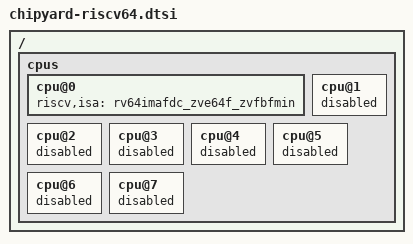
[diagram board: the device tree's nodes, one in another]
/*
 * Copyright (c) 2024 Antmicro <www.antmicro.com>
 *
 * SPDX-License-Identifier: Apache-2.0
 */

/dts-v1/;

#include <chipyard/chipyard-riscv.dtsi>

/ {
	cpus {
		cpu@0 {
			riscv,isa = "rv64imafdc_zve64f_zvfbfmin";
		};

		cpu@1 {
			status = "disabled";
		};

		cpu@2 {
			status = "disabled";
		};

		cpu@3 {
			status = "disabled";
		};

		cpu@4 {
			status = "disabled";
		};

		cpu@5 {
			status = "disabled";
		};

		cpu@6 {
			status = "disabled";
		};

		cpu@7 {
			status = "disabled";
		};
	};
};
